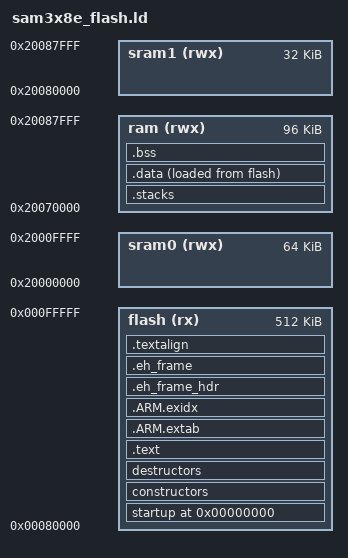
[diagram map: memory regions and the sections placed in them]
/* ----------------------------------------------------------------------------
 *         SAM Software Package License
 * ----------------------------------------------------------------------------
 * Copyright (c) 2012, Atmel Corporation
 *
 * All rights reserved.
 *
 * Redistribution and use in source and binary forms, with or without
 * modification, are permitted provided that the following condition is met:
 *
 * - Redistributions of source code must retain the above copyright notice,
 * this list of conditions and the disclaimer below.
 *
 * Atmel's name may not be used to endorse or promote products derived from
 * this software without specific prior written permission.
 *
 * DISCLAIMER: THIS SOFTWARE IS PROVIDED BY ATMEL "AS IS" AND ANY EXPRESS OR
 * IMPLIED WARRANTIES, INCLUDING, BUT NOT LIMITED TO, THE IMPLIED WARRANTIES OF
 * MERCHANTABILITY, FITNESS FOR A PARTICULAR PURPOSE AND NON-INFRINGEMENT ARE
 * DISCLAIMED. IN NO EVENT SHALL ATMEL BE LIABLE FOR ANY DIRECT, INDIRECT,
 * INCIDENTAL, SPECIAL, EXEMPLARY, OR CONSEQUENTIAL DAMAGES (INCLUDING, BUT NOT
 * LIMITED TO, PROCUREMENT OF SUBSTITUTE GOODS OR SERVICES; LOSS OF USE, DATA,
 * OR PROFITS; OR BUSINESS INTERRUPTION) HOWEVER CAUSED AND ON ANY THEORY OF
 * LIABILITY, WHETHER IN CONTRACT, STRICT LIABILITY, OR TORT (INCLUDING
 * NEGLIGENCE OR OTHERWISE) ARISING IN ANY WAY OUT OF THE USE OF THIS SOFTWARE,
 * EVEN IF ADVISED OF THE POSSIBILITY OF SUCH DAMAGE.
 * ----------------------------------------------------------------------------
 */

OUTPUT_FORMAT("elf32-littlearm", "elf32-littlearm", "elf32-littlearm")
OUTPUT_ARCH(arm)
SEARCH_DIR(.)

/* The stack size used by the application. NOTE: you might need to adjust  */
__main_stack_size__ = DEFINED(__main_stack_size__) ? __main_stack_size__ : 0x0400 ;
__process_stack_size__ = DEFINED(__process_stack_size__) ? __process_stack_size__ : 0x1C00 ;

/* Memory Spaces Definitions */
MEMORY
{
	flash (rx)  : ORIGIN = 0x00080000, LENGTH = 0x00080000 /* Flash, 512K */
	sram0 (rwx) : ORIGIN = 0x20000000, LENGTH = 0x00010000 /* sram0, 64K */
	sram1 (rwx) : ORIGIN = 0x20080000, LENGTH = 0x00008000 /* sram1, 32K */
	ram (rwx)   : ORIGIN = 0x20070000, LENGTH = 0x00018000 /* sram, 96K */
}

__ram_start__           = ORIGIN(ram);
__ram_size__            = LENGTH(ram);
__ram_end__             = __ram_start__ + __ram_size__;

SECTIONS
{
    . = 0;
    _text = .;

    startup : ALIGN(16) SUBALIGN(16)
    {
        KEEP(*(vectors))
    } > flash

    constructors : ALIGN(4) SUBALIGN(4)
    {
        PROVIDE(__init_array_start = .);
        KEEP(*(SORT(.init_array.*)))
        KEEP(*(.init_array))
        PROVIDE(__init_array_end = .);
    } > flash

    destructors : ALIGN(4) SUBALIGN(4)
    {
        PROVIDE(__fini_array_start = .);
        KEEP(*(.fini_array))
        KEEP(*(SORT(.fini_array.*)))
        PROVIDE(__fini_array_end = .);
    } > flash

    .text : ALIGN(16) SUBALIGN(16)
    {
        *(.text.startup.*)
        *(.text)
        *(.text.*)
        *(.rodata)
        *(.rodata.*)
        *(.glue_7t)
        *(.glue_7)
        *(.gcc*)
    } > flash

    .ARM.extab :
    {
        *(.ARM.extab* .gnu.linkonce.armextab.*)
    } > flash

    .ARM.exidx : {
        PROVIDE(__exidx_start = .);
        *(.ARM.exidx* .gnu.linkonce.armexidx.*)
        PROVIDE(__exidx_end = .);
     } > flash

    .eh_frame_hdr :
    {
        *(.eh_frame_hdr)
    } > flash

    .eh_frame : ONLY_IF_RO
    {
        *(.eh_frame)
    } > flash
    
    .textalign : ONLY_IF_RO
    {
        . = ALIGN(8);
    } > flash

    _etext = .;
    _textdata = _etext;

    .stacks :
    {
        . = ALIGN(8);
        __main_stack_base__ = .;
        . += __main_stack_size__;
        . = ALIGN(8);
        __main_stack_end__ = .;
        __process_stack_base__ = .;
        __main_thread_stack_base__ = .;
        . += __process_stack_size__;
        . = ALIGN(8);
        __process_stack_end__ = .;
        __main_thread_stack_end__ = .;
    } > ram

    .data :
    {
        . = ALIGN(4);
        PROVIDE(_data = .);
        *(.data)
        . = ALIGN(4);
        *(.data.*)
        . = ALIGN(4);
        *(.ramtext)
        . = ALIGN(4);
        PROVIDE(_edata = .);
    } > ram AT > flash

    .bss :
    {
        . = ALIGN(4);
        PROVIDE(_bss_start = .);
        *(.bss)
        . = ALIGN(4);
        *(.bss.*)
        . = ALIGN(4);
        *(COMMON)
        . = ALIGN(4);
        PROVIDE(_bss_end = .);
    } > ram    
}

PROVIDE(end = .);
_end            = .;

__heap_base__   = _end;
__heap_end__    = __ram_end__;
